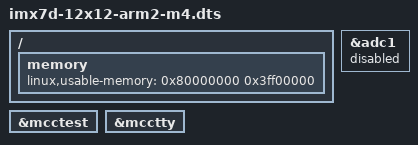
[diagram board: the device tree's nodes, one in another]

#include "imx7d-12x12-arm2.dts"

/ {
	memory {
		linux,usable-memory = <0x80000000 0x3ff00000>;
	};
};

&adc1 {
	status = "disabled";
};

&mcctest{
	status = "okay";
};

&mcctty{
	status = "okay";
};

